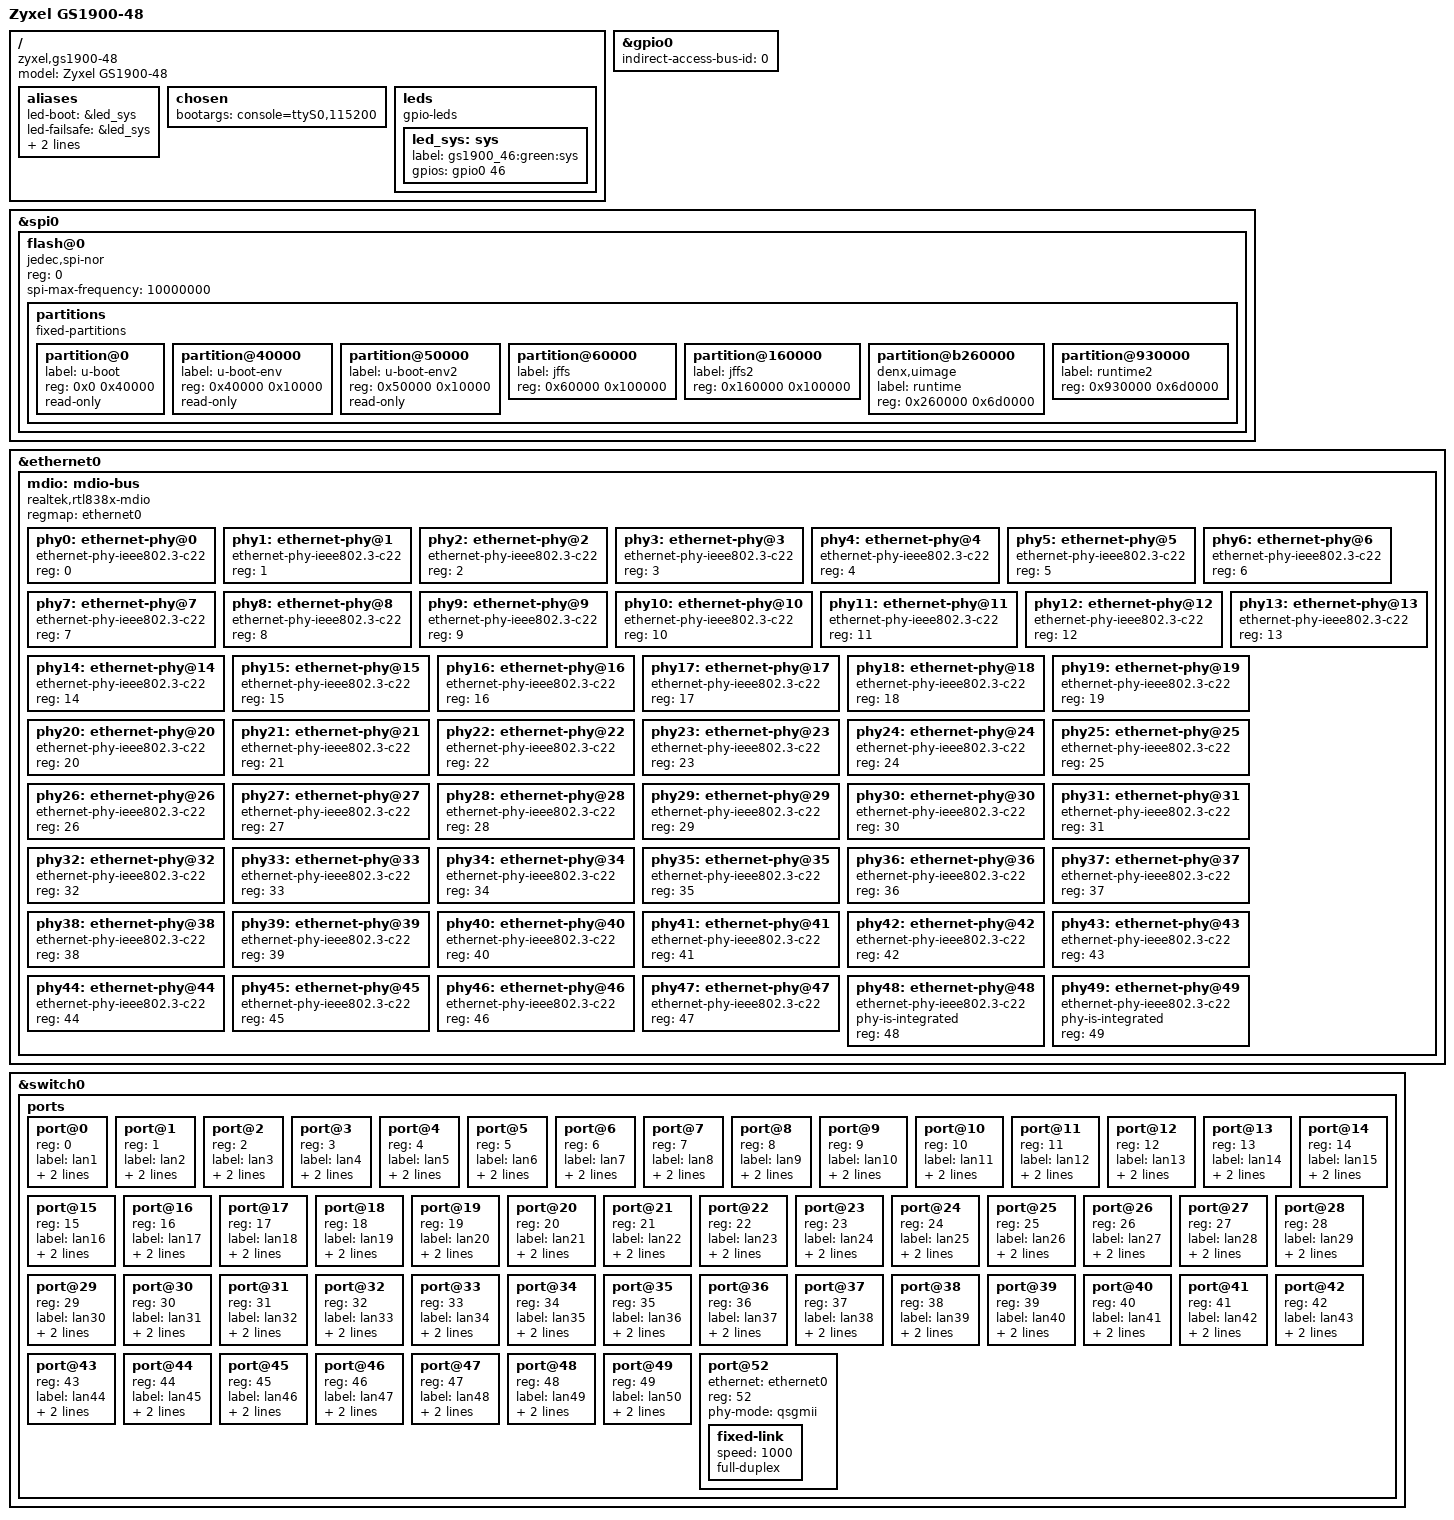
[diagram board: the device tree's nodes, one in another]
/dts-v1/;

#include "rtl839x.dtsi"

#include <dt-bindings/input/input.h>
#include <dt-bindings/gpio/gpio.h>

/ {
	compatible = "zyxel,gs1900-48", "realtek,rtl838x-soc";
	model = "Zyxel GS1900-48";

	aliases {
		led-boot = &led_sys;
		led-failsafe = &led_sys;
		led-running = &led_sys;
		led-upgrade = &led_sys;
	};	

	chosen {
		bootargs = "console=ttyS0,115200";
	};

	leds {
		compatible = "gpio-leds";

		led_sys: sys {
			label = "gs1900_46:green:sys";
			gpios = <&gpio0 46 GPIO_ACTIVE_HIGH>;
		};
	};
};

&gpio0 {
	indirect-access-bus-id = <0>;
};

&spi0 {
	status = "okay";
	flash@0 {
		compatible = "jedec,spi-nor";
		reg = <0>;
		spi-max-frequency = <10000000>;

		partitions {
			compatible = "fixed-partitions";
			#address-cells = <1>;
			#size-cells = <1>;

			partition@0 {
				label = "u-boot";
				reg = <0x0 0x40000>;
				read-only;
			};
			partition@40000 {
				label = "u-boot-env";
				reg = <0x40000 0x10000>;
				read-only;
			};
			partition@50000 {
				label = "u-boot-env2";
				reg = <0x50000 0x10000>;
				read-only;
			};
			partition@60000 {
				label = "jffs";
				reg = <0x60000 0x100000>;
			};
			partition@160000 {
				label = "jffs2";
				reg = <0x160000 0x100000>;
			};
			partition@b260000 {
				label = "runtime";
				reg = <0x260000 0x6d0000>;
				compatible = "denx,uimage";
			};
			partition@930000 {
				label = "runtime2";
				reg = <0x930000 0x6d0000>;
			};
		};
	};
};

&ethernet0 {
	mdio: mdio-bus {
		compatible = "realtek,rtl838x-mdio";
		regmap = <&ethernet0>;
		#address-cells = <1>;
		#size-cells = <0>;
		
		/* External phy RTL8218B #1 */
		phy0: ethernet-phy@0 {
			reg = <0>;
			compatible = "ethernet-phy-ieee802.3-c22";
		};
		phy1: ethernet-phy@1 {
			reg = <1>;
			compatible = "ethernet-phy-ieee802.3-c22";
		};
		phy2: ethernet-phy@2 {
			reg = <2>;
			compatible = "ethernet-phy-ieee802.3-c22";
		};
		phy3: ethernet-phy@3 {
			reg = <3>;
			compatible = "ethernet-phy-ieee802.3-c22";
		};
		phy4: ethernet-phy@4 {
			reg = <4>;
			compatible = "ethernet-phy-ieee802.3-c22";
		};
		phy5: ethernet-phy@5 {
			reg = <5>;
			compatible = "ethernet-phy-ieee802.3-c22";
		};
		phy6: ethernet-phy@6 {
			reg = <6>;
			compatible = "ethernet-phy-ieee802.3-c22";
		};
		phy7: ethernet-phy@7 {
			reg = <7>;
			compatible = "ethernet-phy-ieee802.3-c22";
		};

		/* External phy RTL8218B #2 */
		phy8: ethernet-phy@8 {
			reg = <8>;
			compatible = "ethernet-phy-ieee802.3-c22";
		};
		phy9: ethernet-phy@9 {
			reg = <9>;
			compatible = "ethernet-phy-ieee802.3-c22";
		};
		phy10: ethernet-phy@10 {
			reg = <10>;
			compatible = "ethernet-phy-ieee802.3-c22";
		};
		phy11: ethernet-phy@11 {
			reg = <11>;
			compatible = "ethernet-phy-ieee802.3-c22";
		};
		phy12: ethernet-phy@12 {
			reg = <12>;
			compatible = "ethernet-phy-ieee802.3-c22";
		};
		phy13: ethernet-phy@13 {
			reg = <13>;
			compatible = "ethernet-phy-ieee802.3-c22";
		};
		phy14: ethernet-phy@14 {
			reg = <14>;
			compatible = "ethernet-phy-ieee802.3-c22";
		};
		phy15: ethernet-phy@15 {
			reg = <15>;
			compatible = "ethernet-phy-ieee802.3-c22";
		};

		/* External phy RTL8218B #3 */
		phy16: ethernet-phy@16 {
			reg = <16>;
			compatible = "ethernet-phy-ieee802.3-c22";
		};
		phy17: ethernet-phy@17 {
			reg = <17>;
			compatible = "ethernet-phy-ieee802.3-c22";
		};
		phy18: ethernet-phy@18 {
			reg = <18>;
			compatible = "ethernet-phy-ieee802.3-c22";
		};
		phy19: ethernet-phy@19 {
			reg = <19>;
			compatible = "ethernet-phy-ieee802.3-c22";
		};
		phy20: ethernet-phy@20 {
			reg = <20>;
			compatible = "ethernet-phy-ieee802.3-c22";
		};
		phy21: ethernet-phy@21 {
			reg = <21>;
			compatible = "ethernet-phy-ieee802.3-c22";
		};
		phy22: ethernet-phy@22 {
			reg = <22>;
			compatible = "ethernet-phy-ieee802.3-c22";
		};
		phy23: ethernet-phy@23 {
			reg = <23>;
			compatible = "ethernet-phy-ieee802.3-c22";
		};

		/* External phy RTL8218B #4 */
		phy24: ethernet-phy@24 {
			compatible = "ethernet-phy-ieee802.3-c22";
			reg = <24>;
		};
		phy25: ethernet-phy@25 {
			compatible = "ethernet-phy-ieee802.3-c22";
			reg = <25>;
		};
		phy26: ethernet-phy@26 {
			compatible = "ethernet-phy-ieee802.3-c22";
			reg = <26>;
		};
		phy27: ethernet-phy@27 {
			compatible = "ethernet-phy-ieee802.3-c22";
			reg = <27>;
		};
		phy28: ethernet-phy@28 {
			reg = <28>;
			compatible = "ethernet-phy-ieee802.3-c22";
		};
		phy29: ethernet-phy@29 {
			reg = <29>;
			compatible = "ethernet-phy-ieee802.3-c22";
		};
		phy30: ethernet-phy@30 {
			reg = <30>;
			compatible = "ethernet-phy-ieee802.3-c22";
		};
		phy31: ethernet-phy@31 {
			reg = <31>;
			compatible = "ethernet-phy-ieee802.3-c22";
		};

		/* External phy RTL8218B #5 */
		phy32: ethernet-phy@32 {
			reg = <32>;
			compatible = "ethernet-phy-ieee802.3-c22";
		};
		phy33: ethernet-phy@33 {
			reg = <33>;
			compatible = "ethernet-phy-ieee802.3-c22";
		};
		phy34: ethernet-phy@34 {
			reg = <34>;
			compatible = "ethernet-phy-ieee802.3-c22";
		};
		phy35: ethernet-phy@35 {
			reg = <35>;
			compatible = "ethernet-phy-ieee802.3-c22";
		};
		phy36: ethernet-phy@36 {
			reg = <36>;
			compatible = "ethernet-phy-ieee802.3-c22";
		};
		phy37: ethernet-phy@37 {
			reg = <37>;
			compatible = "ethernet-phy-ieee802.3-c22";
		};
		phy38: ethernet-phy@38 {
			reg = <38>;
			compatible = "ethernet-phy-ieee802.3-c22";
		};
		phy39: ethernet-phy@39 {
			reg = <39>;
			compatible = "ethernet-phy-ieee802.3-c22";
		};

		/* External phy RTL8218B #6 */
		phy40: ethernet-phy@40 {
			reg = <40>;
			compatible = "ethernet-phy-ieee802.3-c22";
		};
		phy41: ethernet-phy@41 {
			reg = <41>;
			compatible = "ethernet-phy-ieee802.3-c22";
		};
		phy42: ethernet-phy@42 {
			reg = <42>;
			compatible = "ethernet-phy-ieee802.3-c22";
		};
		phy43: ethernet-phy@43 {
			reg = <43>;
			compatible = "ethernet-phy-ieee802.3-c22";
		};
		phy44: ethernet-phy@44 {
			reg = <44>;
			compatible = "ethernet-phy-ieee802.3-c22";
		};
		phy45: ethernet-phy@45 {
			reg = <45>;
			compatible = "ethernet-phy-ieee802.3-c22";
		};
		phy46: ethernet-phy@46 {
			reg = <46>;
			compatible = "ethernet-phy-ieee802.3-c22";
		};
		phy47: ethernet-phy@47 {
			reg = <47>;
			compatible = "ethernet-phy-ieee802.3-c22";
		};

		/* RTL8393 Internal Serdes */
		phy48: ethernet-phy@48 {
			compatible = "ethernet-phy-ieee802.3-c22";
			phy-is-integrated;
			reg = <48>;
		};
		phy49: ethernet-phy@49 {
			compatible = "ethernet-phy-ieee802.3-c22";
			phy-is-integrated;
			reg = <49>;
		};

	};
};

&switch0 {
	ports {
		#address-cells = <1>;
		#size-cells = <0>;

		port@0 {
			reg = <0>;
			label = "lan1";
			phy-handle = <&phy0>;
			phy-mode = "qsgmii";
		};
		port@1 {
			reg = <1>;
			label = "lan2";
			phy-handle = <&phy1>;
			phy-mode = "qsgmii";
		};
		port@2 {
			reg = <2>;
			label = "lan3";
			phy-handle = <&phy2>;
			phy-mode = "qsgmii";
		};
		port@3 {
			reg = <3>;
			label = "lan4";
			phy-handle = <&phy3>;
			phy-mode = "qsgmii";
		};
		port@4 {
			reg = <4>;
			label = "lan5";
			phy-handle = <&phy4>;
			phy-mode = "qsgmii";
		};
		port@5 {
			reg = <5>;
			label = "lan6";
			phy-handle = <&phy5>;
			phy-mode = "qsgmii";
		};
		port@6 {
			reg = <6>;
			label = "lan7";
			phy-handle = <&phy6>;
			phy-mode = "qsgmii";
		};
		port@7 {
			reg = <7>;
			label = "lan8";
			phy-handle = <&phy7>;
			phy-mode = "qsgmii";
		};
		
		port@8 {
			reg = <8>;
			label = "lan9";
			phy-handle = <&phy8>;
			phy-mode = "qsgmii";
		};
		port@9 {
			reg = <9>;
			label = "lan10";
			phy-handle = <&phy9>;
			phy-mode = "qsgmii";
		};
		port@10 {
			reg = <10>;
			label = "lan11";
			phy-handle = <&phy10>;
			phy-mode = "qsgmii";
		};
		port@11 {
			reg = <11>;
			label = "lan12";
			phy-handle = <&phy11>;
			phy-mode = "qsgmii";
		};
		port@12 {
			reg = <12>;
			label = "lan13";
			phy-handle = <&phy12>;
			phy-mode = "qsgmii";
		};
		port@13 {
			reg = <13>;
			label = "lan14";
			phy-handle = <&phy13>;
			phy-mode = "qsgmii";
		};
		port@14 {
			reg = <14>;
			label = "lan15";
			phy-handle = <&phy14>;
			phy-mode = "qsgmii";
		};
		port@15 {
			reg = <15>;
			label = "lan16";
			phy-handle = <&phy15>;
			phy-mode = "qsgmii";
		};
		port@16 {
			reg = <16>;
			label = "lan17";
			phy-handle = <&phy16>;
			phy-mode = "qsgmii";
		};
		port@17 {
			reg = <17>;
			label = "lan18";
			phy-handle = <&phy17>;
			phy-mode = "qsgmii";
		};
		port@18 {
			reg = <18>;
			label = "lan19";
			phy-handle = <&phy18>;
			phy-mode = "qsgmii";
		};
		port@19 {
			reg = <19>;
			label = "lan20";
			phy-handle = <&phy19>;
			phy-mode = "qsgmii";
		};
		port@20 {
			reg = <20>;
			label = "lan21";
			phy-handle = <&phy20>;
			phy-mode = "qsgmii";
		};
		port@21 {
			reg = <21>;
			label = "lan22";
			phy-handle = <&phy21>;
			phy-mode = "qsgmii";
		};
		port@22 {
			reg = <22>;
			label = "lan23";
			phy-handle = <&phy22>;
			phy-mode = "qsgmii";
		};
		port@23 {
			reg = <23>;
			label = "lan24";
			phy-handle = <&phy23>;
			phy-mode = "qsgmii";
		};
		port@24 {
			reg = <24>;
			label = "lan25";
			phy-handle = <&phy24>;
			phy-mode = "qsgmii";
		};
		port@25 {
			reg = <25>;
			label = "lan26";
			phy-handle = <&phy25>;
			phy-mode = "qsgmii";
		};
		port@26 {
			reg = <26>;
			label = "lan27";
			phy-handle = <&phy26>;
			phy-mode = "qsgmii";
		};
		port@27 {
			reg = <27>;
			label = "lan28";
			phy-handle = <&phy27>;
			phy-mode = "qsgmii";
		};
		port@28 {
			reg = <28>;
			label = "lan29";
			phy-handle = <&phy28>;
			phy-mode = "qsgmii";
		};
		port@29 {
			reg = <29>;
			label = "lan30";
			phy-handle = <&phy29>;
			phy-mode = "qsgmii";
		};
		port@30 {
			reg = <30>;
			label = "lan31";
			phy-handle = <&phy30>;
			phy-mode = "qsgmii";
		};
		port@31 {
			reg = <31>;
			label = "lan32";
			phy-handle = <&phy31>;
			phy-mode = "qsgmii";
		};
		port@32 {
			reg = <32>;
			label = "lan33";
			phy-handle = <&phy32>;
			phy-mode = "qsgmii";
		};
		port@33 {
			reg = <33>;
			label = "lan34";
			phy-handle = <&phy33>;
			phy-mode = "qsgmii";
		};
		port@34 {
			reg = <34>;
			label = "lan35";
			phy-handle = <&phy34>;
			phy-mode = "qsgmii";
		};
		port@35 {
			reg = <35>;
			label = "lan36";
			phy-handle = <&phy35>;
			phy-mode = "qsgmii";
		};
		port@36 {
			reg = <36>;
			label = "lan37";
			phy-handle = <&phy36>;
			phy-mode = "qsgmii";
		};
		port@37 {
			reg = <37>;
			label = "lan38";
			phy-handle = <&phy37>;
			phy-mode = "qsgmii";
		};
		port@38 {
			reg = <38>;
			label = "lan39";
			phy-handle = <&phy38>;
			phy-mode = "qsgmii";
		};
		port@39 {
			reg = <39>;
			label = "lan40";
			phy-handle = <&phy39>;
			phy-mode = "qsgmii";
		};
		port@40 {
			reg = <40>;
			label = "lan41";
			phy-handle = <&phy40>;
			phy-mode = "qsgmii";
		};
		port@41 {
			reg = <41>;
			label = "lan42";
			phy-handle = <&phy41>;
			phy-mode = "qsgmii";
		};
		port@42 {
			reg = <42>;
			label = "lan43";
			phy-handle = <&phy42>;
			phy-mode = "qsgmii";
		};
		port@43 {
			reg = <43>;
			label = "lan44";
			phy-handle = <&phy43>;
			phy-mode = "qsgmii";
		};
		port@44 {
			reg = <44>;
			label = "lan45";
			phy-handle = <&phy44>;
			phy-mode = "qsgmii";
		};
		port@45 {
			reg = <45>;
			label = "lan46";
			phy-handle = <&phy45>;
			phy-mode = "qsgmii";
		};
		port@46 {
			reg = <46>;
			label = "lan47";
			phy-handle = <&phy46>;
			phy-mode = "qsgmii";
		};
		port@47 {
			reg = <47>;
			label = "lan48";
			phy-handle = <&phy47>;
			phy-mode = "qsgmii";
		};

		/* RTL8393 Internal SerDes */
		port@48 {
			reg = <48>;
			label = "lan49";
			phy-mode = "internal";
			phy-handle = <&phy48>;
		};
		port@49 {
			reg = <49>;
			label = "lan50";
			phy-mode = "internal";
			phy-handle = <&phy49>;
		};

		/* CPU-Port */
		port@52 {
			ethernet = <&ethernet0>;
			reg = <52>;
			phy-mode = "qsgmii";
			fixed-link {
				speed = <1000>;
				full-duplex;
			};
		};
	};
};
